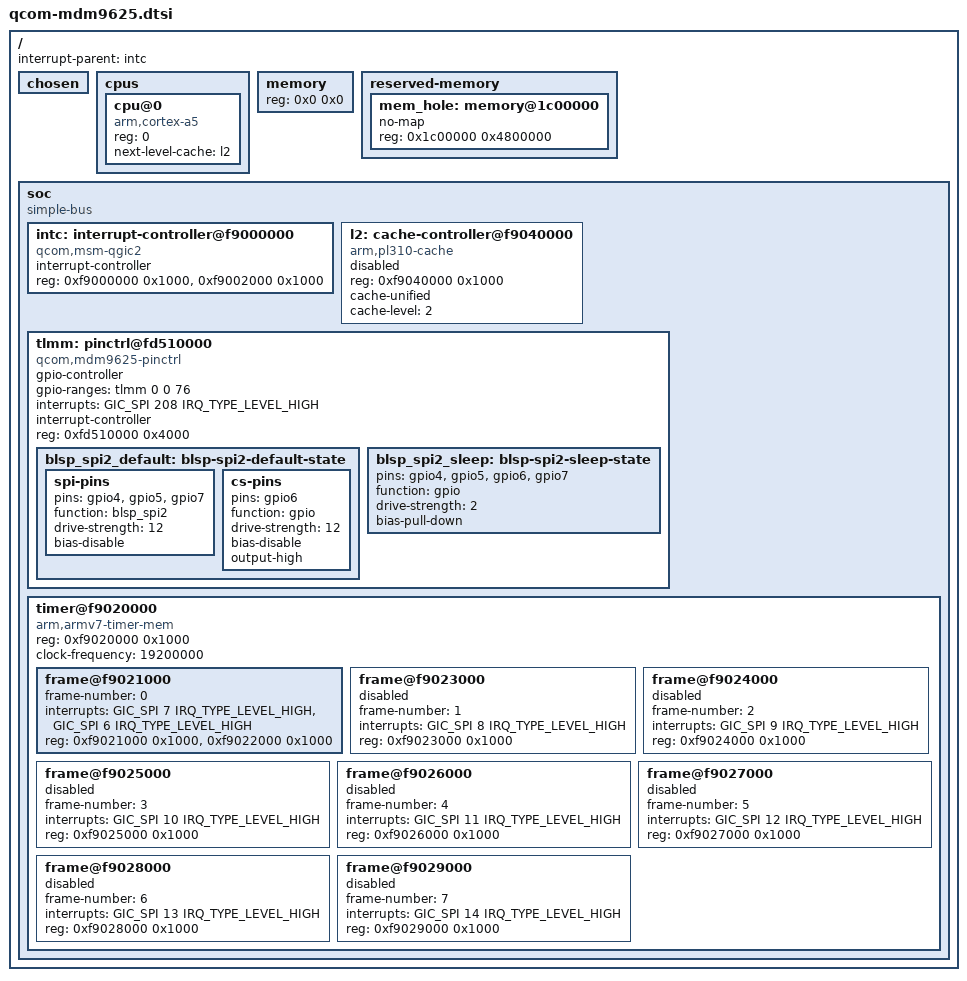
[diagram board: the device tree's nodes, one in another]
/dts-v1/;

#include <dt-bindings/interrupt-controller/irq.h>
#include <dt-bindings/interrupt-controller/arm-gic.h>
#include <dt-bindings/gpio/gpio.h>

/ {
	#address-cells = <1>;
	#size-cells = <1>;
	interrupt-parent = <&intc>;

	chosen { };

	cpus {
		#address-cells = <1>;
		#size-cells = <0>;

		cpu@0 {
			device_type = "cpu";
			compatible = "arm,cortex-a5";
			reg = <0>;
			next-level-cache = <&l2>;
		};
	};

	memory {
		device_type = "memory";
		// Bootloader will fill this in.. probably
		reg = <0x0 0x0>;
	};

	reserved-memory {
		#address-cells = <1>;
		#size-cells = <1>;
		ranges;

		mem_hole: memory@1c00000 {
			no-map;
			reg = <0x1c00000 0x4800000>;
		};
	};

	soc: soc {
		compatible = "simple-bus";
		#address-cells = <1>;
		#size-cells = <1>;
		ranges;

		intc: interrupt-controller@f9000000 {
			compatible = "qcom,msm-qgic2";
			interrupt-controller;
			#interrupt-cells = <3>;
			reg = <0xf9000000 0x1000>,
			      <0xf9002000 0x1000>;
		};

		l2: cache-controller@f9040000 {
			compatible = "arm,pl310-cache";
			reg = <0xf9040000 0x1000>;
			cache-unified;
			cache-level = <2>;
			status = "disabled"; // TZ needs to power this up?
		};

		tlmm: pinctrl@fd510000 {
			compatible = "qcom,mdm9625-pinctrl";
			gpio-controller;
			gpio-ranges = <&tlmm 0 0 76>;
			#gpio-cells = <2>;
			interrupts = <GIC_SPI 208 IRQ_TYPE_LEVEL_HIGH>;
			interrupt-controller;
			#interrupt-cells = <2>;
			reg = <0xfd510000 0x4000>;

			blsp_spi2_default: blsp-spi2-default-state {
				spi-pins {
					pins = "gpio4", "gpio5", "gpio7";
					function = "blsp_spi2";
					drive-strength = <12>;
					bias-disable;
				};
				cs-pins {
					pins = "gpio6";
					function = "gpio";
					drive-strength = <12>;
					bias-disable;
					output-high;
				};
			};

			blsp_spi2_sleep: blsp-spi2-sleep-state {
				pins = "gpio4", "gpio5", "gpio6", "gpio7";
				function = "gpio";
				drive-strength = <2>;
				bias-pull-down;
			};
		};

		timer@f9020000 {
			#address-cells = <1>;
			#size-cells = <1>;
			ranges;
			compatible = "arm,armv7-timer-mem";
			reg = <0xf9020000 0x1000>;
			clock-frequency = <19200000>;

			frame@f9021000 {
				frame-number = <0>;
				interrupts = <GIC_SPI 7 IRQ_TYPE_LEVEL_HIGH>,
					    	 <GIC_SPI 6 IRQ_TYPE_LEVEL_HIGH>;
				reg = <0xf9021000 0x1000>,
				      <0xf9022000 0x1000>;
			};

			frame@f9023000 {
				frame-number = <1>;
				interrupts = <GIC_SPI 8 IRQ_TYPE_LEVEL_HIGH>;
				reg = <0xf9023000 0x1000>;
				status = "disabled";
			};

			frame@f9024000 {
				frame-number = <2>;
				interrupts = <GIC_SPI 9 IRQ_TYPE_LEVEL_HIGH>;
				reg = <0xf9024000 0x1000>;
				status = "disabled";
			};

			frame@f9025000 {
				frame-number = <3>;
				interrupts = <GIC_SPI 10 IRQ_TYPE_LEVEL_HIGH>;
				reg = <0xf9025000 0x1000>;
				status = "disabled";
			};

			frame@f9026000 {
				frame-number = <4>;
				interrupts = <GIC_SPI 11 IRQ_TYPE_LEVEL_HIGH>;
				reg = <0xf9026000 0x1000>;
				status = "disabled";
			};

			frame@f9027000 {
				frame-number = <5>;
				interrupts = <GIC_SPI 12 IRQ_TYPE_LEVEL_HIGH>;
				reg = <0xf9027000 0x1000>;
				status = "disabled";
			};

			frame@f9028000 {
				frame-number = <6>;
				interrupts = <GIC_SPI 13 IRQ_TYPE_LEVEL_HIGH>;
				reg = <0xf9028000 0x1000>;
				status = "disabled";
			};

			frame@f9029000 {
				frame-number = <7>;
				interrupts = <GIC_SPI 14 IRQ_TYPE_LEVEL_HIGH>;
				reg = <0xf9029000 0x1000>;
				status = "disabled";
			};
		};
	};
};
